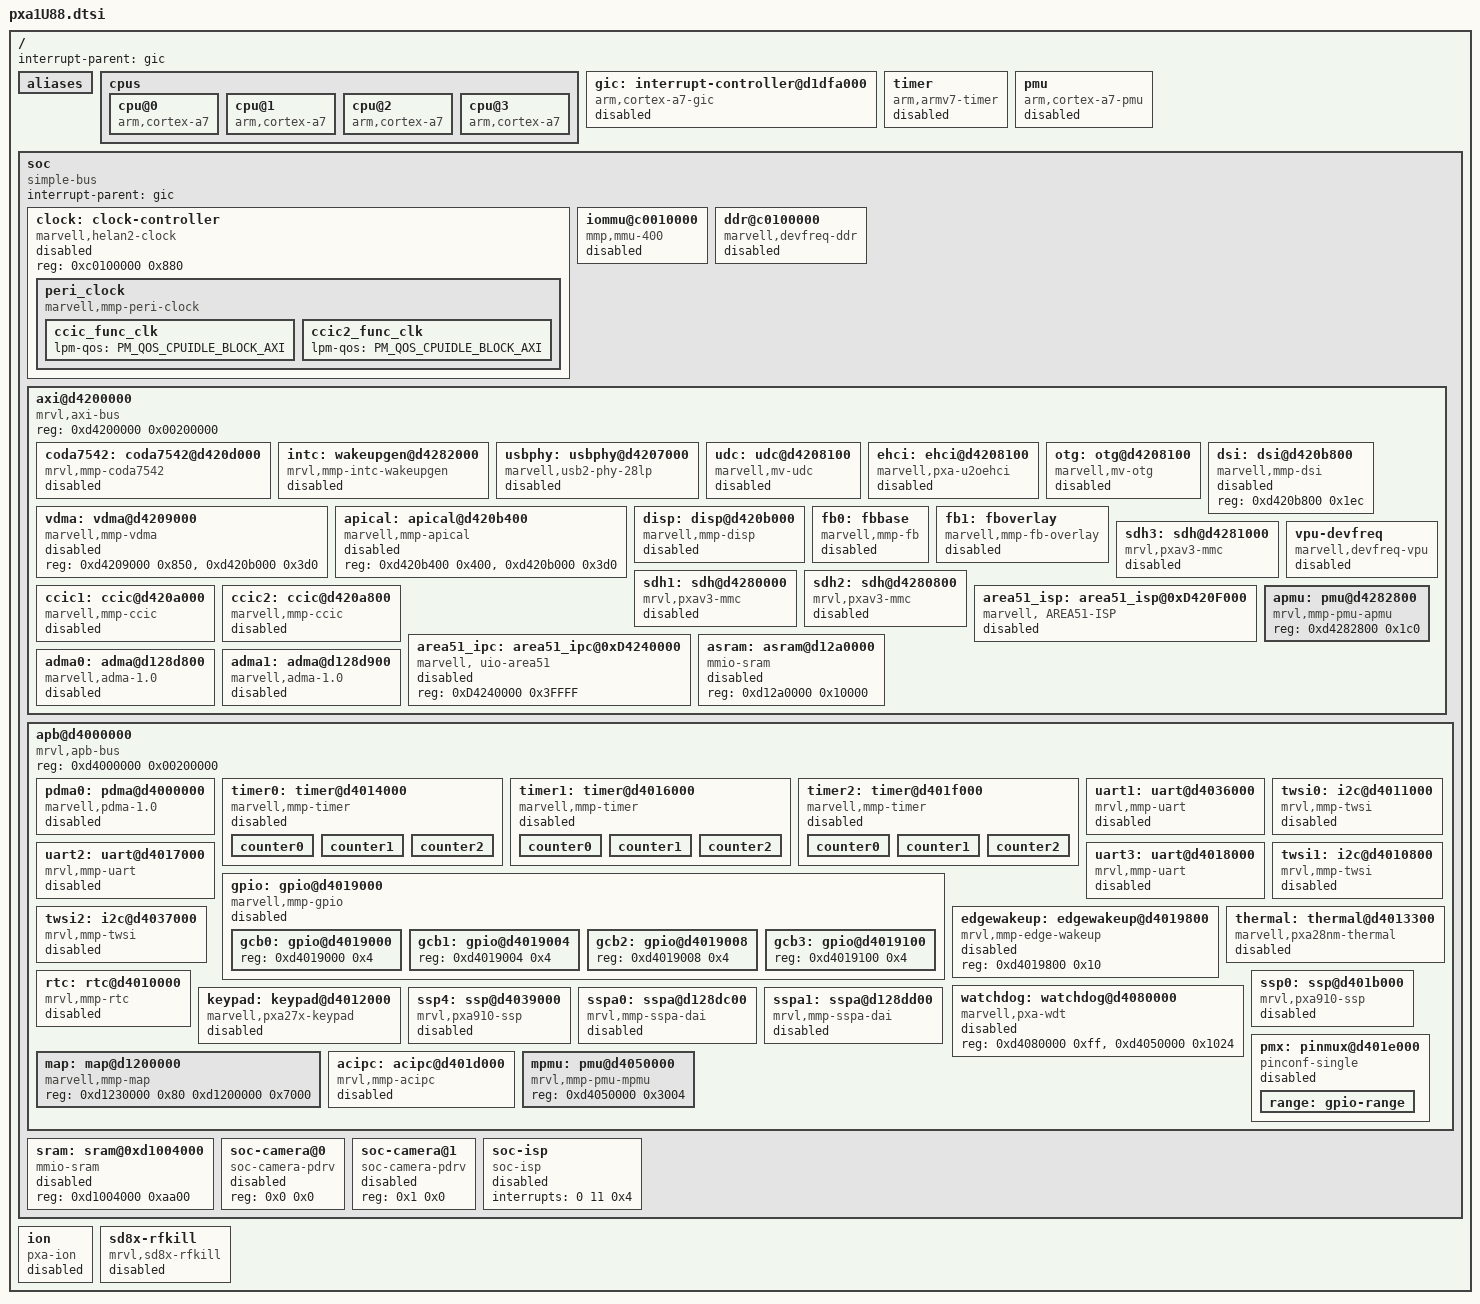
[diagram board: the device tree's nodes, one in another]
/*
 *  Copyright (C) 2013 Marvell Technology Group Ltd.
 *  Author: Chao Xie <chao.xie@marvell.com>
 *
 *  This program is free software; you can redistribute it and/or modify
 *  it under the terms of the GNU General Public License version 2 as
 *  publishhed by the Free Software Foundation.
 */

/include/ "skeleton.dtsi"
#include "pxa988-pm.h"
#include "pxa988-pinfunc.h"
#include <dt-bindings/usb/mv_usb_phy.h>

/ {
	interrupt-parent = <&gic>;

	aliases {
		serial0 = &uart1;
		serial1 = &uart2;
		serial2 = &uart3;
		i2c0 = &twsi0;
		i2c1 = &twsi1;
		i2c2 = &twsi2;
		mmp-camera0 = &ccic1;
		mmp-camera1 = &ccic2;
	};

	cpus {
		cpu@0 {
			compatible = "arm,cortex-a7";
		};
		cpu@1 {
			compatible = "arm,cortex-a7";
		};
		cpu@2 {
			compatible = "arm,cortex-a7";
		};
		cpu@3 {
			compatible = "arm,cortex-a7";
		};
	};

	gic: interrupt-controller@d1dfa000 {
		compatible = "arm,cortex-a7-gic";
		interrupt-controller;
		#interrupt-cells = <3>;
		reg = <0xd1df9000 0x1000>,
		      <0xd1dfa000 0x2000>;
		status = "disabled";
	};

	timer {
		compatible = "arm,armv7-timer";
		/* PPI secure/nonsecure IRQ, active low level-sensitive */
		interrupts = <1 13 0x308>,
			     <1 14 0x308>,
			     <1 11 0x308>,
			     <1 10 0x308>;
		clock-frequency = <26000000>;
		status = "disabled";
	};

	pmu {
		compatible = "arm,cortex-a7-pmu";
		interrupts = <0 58 0x04
			      0 61 0x04
			      0 66 0x04
			      0 68 0x04>;
		status = "disabled";
	};

	soc {
		#address-cells = <1>;
		#size-cells = <1>;
		compatible = "simple-bus";
		interrupt-parent = <&gic>;
		ranges;

		clock: clock-controller {
			compatible = "marvell,helan2-clock";
			reg = <0xc0100000 0x880>;
			reg-names = "dmcu";
			status = "disabled";
			peri_clock {
				compatible = "marvell,mmp-peri-clock";
				ccic_func_clk {
					lpm-qos = <PM_QOS_CPUIDLE_BLOCK_AXI>;
				};

				ccic2_func_clk {
					lpm-qos = <PM_QOS_CPUIDLE_BLOCK_AXI>;
				};
			};
		};

		iommu@c0010000 {
			compatible = "mmp,mmu-400";
			interrupts = <0 78 0x4>;
			reg = <0xc0010000 0x10000>;
			status = "disabled";
		};

		ddr@c0100000 {  /* DDR memory controller */
			compatible = "marvell,devfreq-ddr";
			reg = <0xc0100000 0x880>;
			marvell,qos;
			status = "disabled";
		};

		axi@d4200000 {	/* AXI */
			compatible = "mrvl,axi-bus", "simple-bus";
			#address-cells = <1>;
			#size-cells = <1>;
			reg = <0xd4200000 0x00200000>;
			ranges;

			coda7542: coda7542@d420d000 {
				compatible = "mrvl,mmp-coda7542";
				reg = <0xd420d000 0x1000>,
				      <0xd1004000 0x11600>;
				interrupts = <0 25 0x4>;
				status = "disabled";
			};

			intc: wakeupgen@d4282000 {
				compatible = "mrvl,mmp-intc-wakeupgen";
				reg = <0xd4282000 0x1000>,
				      <0xd4282800 0x12c>;
				mrvl,intc-nr-irqs = <96>;
				mrvl,intc-gbl-mask = <0x228 0x3
						     0x238 0x3
						     0x248 0x3
						     0x258 0x3>;
				mrvl,intc-for-cp = <0 31 32>;
				mrvl,intc-wake-clr = <9  (1 << 3)
						      39 (1 << 0 | 1 << 1 | 1 << 6)>;
				status = "disabled";
			};

			usbphy: usbphy@d4207000 {
				compatible = "marvell,usb2-phy-28lp";
				reg = <0xd4207000 0x200>;
				marvell,udc-name = "mv-udc";
				marvell,ehci-name = "pxa-u2oehci";
				marvell,otg-name = "mv-otg";
				status = "disabled";
			};

			udc: udc@d4208100 {
				compatible = "marvell,mv-udc";
				reg = <0xd4208100 0x200>;
				interrupts = <0 44 0x4>;
				lpm-qos = <PM_QOS_CPUIDLE_BLOCK_AXI>;
				status = "disabled";
			};

			ehci: ehci@d4208100 {
				compatible = "marvell,pxa-u2oehci";
				reg = <0xd4208100 0x200>;
				interrupts = <0 44 0x4>;
				status = "disabled";
			};

			otg: otg@d4208100 {
				compatible = "marvell,mv-otg";
				reg = <0xd4208100 0x200>;
				interrupts = <0 44 0x4>;
				marvell,udc-name = "mv-udc";
				marvell,ehci-name = "pxa-u2oehci";
				lpm-qos = <PM_QOS_CPUIDLE_BLOCK_AXI>;
				status = "disabled";
			};

			dsi: dsi@d420b800 {
				compatible = "marvell,mmp-dsi";
				reg = <0xd420b800 0x1ec>;
				status = "disabled";
			};

			vdma: vdma@d4209000 {
				compatible = "marvell,mmp-vdma";
				reg = <0xd4209000 0x850>, <0xd420b000 0x3d0>;
				status = "disabled";
			};

			apical: apical@d420b400 {
				compatible = "marvell,mmp-apical";
				reg = <0xd420b400 0x400>, <0xd420b000 0x3d0>;
				status = "disabled";
			};

			disp: disp@d420b000 {
				compatible = "marvell,mmp-disp";
				reg = <0xd420b000 0x3d0>;
				lpm-qos = <PM_QOS_CPUIDLE_BLOCK_DDR>;
				interrupts = <0 41 0x4>;
				status = "disabled";
			};

			fb0: fbbase {
				compatible = "marvell,mmp-fb";
				status = "disabled";
			};

			fb1: fboverlay {
				compatible = "marvell,mmp-fb-overlay";
				status = "disabled";
			};

			sdh3: sdh@d4281000 {
				compatible = "mrvl,pxav3-mmc";
				reg = <0xd4281000 0x120>;
				interrupts = <0 39 0x4>;
				lpm-qos = <PM_QOS_CPUIDLE_BLOCK_AXI>;
				status = "disabled";
			 };

			sdh1: sdh@d4280000 {
				compatible = "mrvl,pxav3-mmc";
				reg = <0xd4280000 0x120>;
				interrupts = <0 39 0x4>;
				lpm-qos = <PM_QOS_CPUIDLE_BLOCK_AXI>;
				status = "disabled";
			};

			sdh2: sdh@d4280800 {
				compatible = "mrvl,pxav3-mmc";
				reg = <0xd4280800 0x120>;
				interrupts = <0 39 0x4>;
				lpm-qos = <PM_QOS_CPUIDLE_BLOCK_AXI>;
				status = "disabled";
			};

			ccic1: ccic@d420a000 {
				   compatible = "marvell,mmp-ccic";
				   reg = <0xd420a000 0x2ff>, <0xd4282800 0x1ff>;
				   reg-names = "ccic-regs", "apmu-regs";
				   dma-burst = <64>;
				   mclk-src = <3>;
				   mclk-div = <17>;
				   interrupts = <0 42 0x4>;
				   status = "disable";
			};

			ccic2: ccic@d420a800 {
				   compatible = "marvell,mmp-ccic";
				   reg = <0xd420a800 0x2ff>, <0xd4282800 0x1ff>;
				   reg-names = "ccic-regs", "apmu-regs";
				   dma-burst = <64>;
				   mclk-src = <3>;
				   mclk-div = <17>;
				   interrupts = <0 77 0x4>;
				   status = "disable";
			};

			vpu-devfreq {
				compatible = "marvell,devfreq-vpu";
				status = "disabled";
			};

			area51_isp: area51_isp@0xD420F000 {
				compatible = "marvell, AREA51-ISP";
				reg = <0xD420F000 0xFFFF>;
				reg-name = "area51-regs";
				interrupts = <0 15 0x4>;
				status = "disabled";
			};

			area51_ipc: area51_ipc@0xD4240000 {
				compatible = "marvell, uio-area51";
				reg = <0xD4240000 0x3FFFF>;
				status = "disabled";
			};

			apmu: pmu@d4282800 {
				compatible = "mrvl,mmp-pmu-apmu";
				reg = <0xd4282800 0x1c0>;
			};

			asram: asram@d12a0000 {
				compatible = "mmio-sram";
				reg = <0xd12a0000 0x10000>;
				status = "disabled";
			};

			adma0: adma@d128d800 {
				compatible = "marvell,adma-1.0";
				reg = <0xD128D800 0x100>;
				interrupts = <0 82 0x4>;
				#dma-cells = <1>;
				asram = <&asram>;
				status = "disabled";
			};

			adma1: adma@d128d900 {
				compatible = "marvell,adma-1.0";
				reg = <0xD128D900 0x100>;
				interrupts = <0 83 0x4>;
				#dma-cells = <1>;
				asram = <&asram>;
				status = "disabled";
			};
		};

		apb@d4000000 {	/* APB */
			compatible = "mrvl,apb-bus", "simple-bus";
			#address-cells = <1>;
			#size-cells = <1>;
			reg = <0xd4000000 0x00200000>;
			ranges;

			pdma0: pdma@d4000000 {
				compatible = "marvell,pdma-1.0";
				reg = <0xd4000000 0x10000>;
				interrupts = <0 47 0x4>;
				#dma-cells= <2>;
				#dma-channels = <32>;
				#dma-channels-tz = <30>;
				lpm-qos = <PM_QOS_CPUIDLE_BLOCK_AXI>;
				status = "disabled";
			};

			timer0: timer@d4014000 {
				compatible = "marvell,mmp-timer";
				reg = <0xd4014000 0xc8>;
				marvell,timer-id = <0>;
				marvell,timer-flag = <0>;
				marvell,timer-fc_freq = <3250000>;
				marvell,timer-apb_freq = <26000000>;
				status = "disabled";

				counter0 {
					interrupts = <0 13 0x4>;
					marvell,timer-counter-id = <0>;
					marvell,timer-counter-cpu = <0>;
					marvell,timer-counter-cnt_freq = <32768>;
					marvell,timer-counter-usage = <4>;
					marvell,timer-counter-cnt_rating = <200>;
					marvell,timer-counter-mode = <1>;
				};

				counter1 {
					interrupts = <0 14 0x4>;
					marvell,timer-counter-id = <1>;
					marvell,timer-counter-cpu = <1>;
					marvell,timer-counter-cnt_freq = <32768>;
					marvell,timer-counter-usage = <4>;
					marvell,timer-counter-cnt_rating = <200>;
					marvell,timer-counter-mode = <1>;
				};

				counter2 {
					interrupts = <0 2 0x4>;
					marvell,timer-counter-id = <2>;
					marvell,timer-counter-cpu = <0>;
					marvell,timer-counter-cnt_freq = <32768>;
					marvell,timer-counter-usage = <1>;
					marvell,timer-counter-cnt_rating = <200>;
					marvell,timer-counter-mode = <0>;
				};
			};

			timer1: timer@d4016000 {
				compatible = "marvell,mmp-timer";
				reg = <0xd4016000 0xc8>;
				marvell,timer-id = <1>;
				marvell,timer-flag = <0>;
				marvell,timer-fc_freq = <3250000>;
				marvell,timer-apb_freq = <26000000>;
				status = "disabled";

				counter0 {
					interrupts = <0 29 0x4>;
					marvell,timer-counter-id = <0>;
					marvell,timer-counter-cpu = <2>;
					marvell,timer-counter-cnt_freq = <32768>;
					marvell,timer-counter-usage = <4>;
					marvell,timer-counter-cnt_rating = <200>;
					marvell,timer-counter-mode = <1>;
				};

				counter1 {
					interrupts = <0 30 0x4>;
					marvell,timer-counter-id = <1>;
					marvell,timer-counter-cpu = <3>;
					marvell,timer-counter-cnt_freq = <32768>;
					marvell,timer-counter-usage = <4>;
					marvell,timer-counter-cnt_rating = <200>;
					marvell,timer-counter-mode = <1>;
				};

				counter2 {
					interrupts = <0 46 0x4>;
					marvell,timer-counter-id = <2>;
					marvell,timer-counter-cpu = <0>;
					marvell,timer-counter-cnt_freq = <3250000>;
					marvell,timer-counter-usage = <8>;
					marvell,timer-counter-cnt_rating = <200>;
					marvell,timer-counter-mode = <0>;
				};
			};

			timer2: timer@d401f000 {
				compatible = "marvell,mmp-timer";
				reg = <0xd401f000 0xc8>;
				marvell,timer-id = <2>;
				marvell,timer-flag = <5>;
				marvell,timer-fc_freq = <3250000>;
				marvell,timer-apb_freq = <26000000>;
				status = "disabled";

				counter0 {
					interrupts = <0 64 0x4>;
					marvell,timer-counter-id = <0>;
					marvell,timer-counter-cpu = <0>;
					marvell,timer-counter-cnt_freq = <3250000>;
					marvell,timer-counter-usage = <18>;
					marvell,timer-counter-cnt_rating = <200>;
					marvell,timer-counter-mode = <1>;
				};

				counter1 {
					interrupts = <0 65 0x4>;
					marvell,timer-counter-id = <1>;
					marvell,timer-counter-cpu = <3>;
					marvell,timer-counter-cnt_freq = <32768>;
					marvell,timer-counter-usage = <0>;
					marvell,timer-counter-cnt_rating = <200>;
					marvell,timer-counter-mode = <1>;
				};

				counter2 {
					interrupts = <0 62 0x4>;
					marvell,timer-counter-id = <2>;
					marvell,timer-counter-cpu = <0>;
					marvell,timer-counter-cnt_freq = <3250000>;
					marvell,timer-counter-usage = <0>;
					marvell,timer-counter-cnt_rating = <200>;
					marvell,timer-counter-mode = <0>;
				};
			};

			uart1: uart@d4036000 {
				compatible = "mrvl,mmp-uart";
				reg = <0xd4036000 0x1000>;
				interrupts = <0 59 0x4>;
				dmas = <&pdma0 4 1
					&pdma0 5 1>;
				dma-names = "rx", "tx";
				lpm-qos = <PM_QOS_CPUIDLE_BLOCK_AXI>;
				status = "disabled";
			};

			uart2: uart@d4017000 {
				compatible = "mrvl,mmp-uart";
				reg = <0xd4017000 0x1000>;
				interrupts = <0 27 0x4>;
				dmas = <&pdma0 21 1
					&pdma0 22 1>;
				dma-names = "rx", "tx";
				lpm-qos = <PM_QOS_CPUIDLE_BLOCK_AXI>;
				status = "disabled";
			};

			uart3: uart@d4018000 {
				compatible = "mrvl,mmp-uart";
				reg = <0xd4018000 0x1000>;
				interrupts = <0 28 0x4>;
				dmas = <&pdma0 23 1
					&pdma0 24 1>;
				dma-names = "rx", "tx";
				lpm-qos = <PM_QOS_CPUIDLE_BLOCK_AXI>;
				status = "disabled";
			};

			gpio: gpio@d4019000 {
				compatible = "marvell,mmp-gpio";
				#address-cells = <1>;
				#size-cells = <1>;
				reg = <0xd4019000 0x800>;
				gpio-controller;
				#gpio-cells = <2>;
				interrupts = <0 49 0x4>;
				interrupt-names = "gpio_mux";
				interrupt-controller;
				#interrupt-cells = <2>;
				ranges;

				status = "disabled";

				gcb0: gpio@d4019000 {
					reg = <0xd4019000 0x4>;
				};

				gcb1: gpio@d4019004 {
					reg = <0xd4019004 0x4>;
				};

				gcb2: gpio@d4019008 {
					reg = <0xd4019008 0x4>;
				};

				gcb3: gpio@d4019100 {
					reg = <0xd4019100 0x4>;
				};
			};

			edgewakeup: edgewakeup@d4019800 {
				compatible = "mrvl,mmp-edge-wakeup";
				reg = <0xd4019800 0x10>;
				status = "disabled";
			};

			twsi0: i2c@d4011000 {
				compatible = "mrvl,mmp-twsi";
				#address-cells = <1>;
				#size-cells = <0>;
				reg = <0xd4011000 0x60>;
				interrupts = <0 7 0x4>;
				lpm-qos = <PM_QOS_CPUIDLE_BLOCK_DDR>;
				mrvl,i2c-fast-mode;
				/*
				 *ilcr: fast mode b17~9=0x23, 390k
				 *      standard mode b8~0=0x9f, 97k
				 *iwcr: b5~0=b01010 recommended value from spec
				 */
				marvell,i2c-ilcr = <0x82c469f>;
				marvell,i2c-iwcr = <0x142a>;
				status = "disabled";
			};

			twsi1: i2c@d4010800 {
				compatible = "mrvl,mmp-twsi";
				#address-cells = <1>;
				#size-cells = <0>;
				reg = <0xd4010800 0x60>;
				interrupts = <0 33 0x4>;
				lpm-qos = <PM_QOS_CPUIDLE_BLOCK_DDR>;

				mrvl,i2c-fast-mode;
				marvell,i2c-ilcr = <0x82c469f>;
				marvell,i2c-iwcr = <0x142a>;

				status = "disabled";
			};

			twsi2: i2c@d4037000 {
				compatible = "mrvl,mmp-twsi";
				#address-cells = <1>;
				#size-cells = <0>;
				/* RIPC3 */
				reg = <0xd4037000 0x60>,
				      <0xd403d300 0x4>;
				interrupts = <0 54 0x4>;
				lpm-qos = <PM_QOS_CPUIDLE_BLOCK_DDR>;

				mrvl,i2c-fast-mode;
				marvell,i2c-ilcr = <0x82c469f>;
				marvell,i2c-iwcr = <0x142a>;

				marvell,i2c-always-on;
				status = "disabled";
			};

			thermal: thermal@d4013300 {
				compatible = "marvell,pxa28nm-thermal";
				reg = <0xd4013300 0x1C>;
				interrupts = <0 60 0x4>;
				status = "disabled";
			};

			watchdog: watchdog@d4080000 {
				compatible = "marvell,pxa-wdt";
				reg = <0xd4080000 0xff>,
				      <0xd4050000 0x1024>;
				status = "disabled";
			};

			rtc: rtc@d4010000 {
				compatible = "mrvl,mmp-rtc";
				reg = <0xd4010000 0x100>;
				interrupts = <0 5 0x4>,<0 6 0x4>;
				interrupt-names = "rtc 1Hz", "rtc alarm";
				status = "disabled";
			};

			keypad: keypad@d4012000 {
				compatible = "marvell,pxa27x-keypad";
				reg = <0xd4012000 0x4c>;
				lpm-qos = <PM_QOS_CPUIDLE_BLOCK_DDR>;
				interrupts = <0 9 0x4>;
				status = "disabled";
			};

			ssp0: ssp@d401b000 {
				compatible = "mrvl,pxa910-ssp";
				reg = <0xd401b000 0x90>;
				ssp-id = <1>;
				interrupts = <0 3 0x4>;
				status = "disabled";
			};

			ssp4: ssp@d4039000 {
				compatible = "mrvl,pxa910-ssp";
				reg = <0xd4039000 0x90>;
				ssp-id = <5>;
				interrupts = <0 34 0x4>;
				status = "disabled";
			};

			sspa0: sspa@d128dc00 {
				compatible = "mrvl,mmp-sspa-dai";
				reg = <0xd128dc00 0x100>;
				dmas = <&adma0 1
					&adma0 0>;
				dma-names = "rx", "tx";
				asram = <&asram>;
				platform_driver_name = "tdma_platform";
				status = "disabled";
			};

			sspa1: sspa@d128dd00 {
				compatible = "mrvl,mmp-sspa-dai";
				reg = <0xd128dd00 0x100>;
				dmas = <&adma1 1
					&adma1 0>;
				dma-names = "rx", "tx";
				asram = <&asram>;
				platform_driver_name = "tdma_platform";
				status = "disabled";
			};

			map: map@d1200000 {
				compatible = "marvell,mmp-map";
				reg = <0xd1230000 0x80
					0xd1200000 0x7000>;
			};

			pmx: pinmux@d401e000 {
				compatible = "pinconf-single";
				reg = <0xd401e000 0x330>;
				#address-cells = <1>;
				#size-cells = <1>;
				#gpio-range-cells = <3>;
				ranges;

				status = "disabled";

				pinctrl-single,register-width = <32>;
				pinctrl-single,function-mask = <7>;

				range: gpio-range {
					#pinctrl-single,gpio-range-cells = <3>;
				};
			};

			acipc: acipc@d401d000 {
				compatible = "mrvl,mmp-acipc";
				reg = <0xd401d000 0x100>;
				interrupts = <0 16 0x4>,<0 17 0x4>,<0 18 0x4>;
				interrupt-names = "IPC_AP_DATAACK", "IPC_AP_SET_CMD", "IPC_AP_SET_MSG";
				status = "disabled";
			};

			mpmu: pmu@d4050000 {
				compatible = "mrvl,mmp-pmu-mpmu";
				reg = <0xd4050000 0x3004>;
			};
		};

		sram: sram@0xd1004000 {
			compatible = "mmio-sram";
			reg = <0xd1004000 0xaa00>;
			status = "disabled";
		};

		soc-camera@0 {
			compatible = "soc-camera-pdrv";
			status = "disabled";
			reg = <0x0 0x0>;
		};

		soc-camera@1 {
			compatible = "soc-camera-pdrv";
			status = "disabled";
			reg = <0x1 0x0>;
		};

		soc-isp {
			compatible = "soc-isp";
			interrupts = <0 11 0x4>;
			status = "disabled";
		};

	};

	ion {
		compatible = "pxa-ion";
		status = "disabled";
	};

	sd8x-rfkill {
		compatible = "mrvl,sd8x-rfkill";
		status = "disabled";
	};
};
